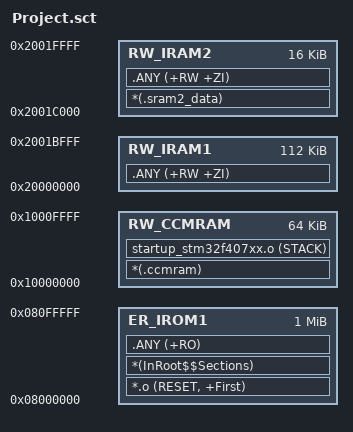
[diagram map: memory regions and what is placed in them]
; *************************************************************
; *** Scatter-Loading Description File generated by uVision ***
; *************************************************************

LR_IROM1 0x08000000 0x00100000  {    ; load region size_region
  ER_IROM1 0x08000000 0x00100000  {  ; load address = execution address
   *.o (RESET, +First)
   *(InRoot$$Sections)
   .ANY (+RO)
  }
  ; 1. CCMRAM：仅 CPU 访问的高速数据区
  ;CCM需要开时钟，可是时钟恰好就是开的！（默认复位置1）
  RW_CCMRAM 0x10000000 0x00010000 {
    *(.ccmram)                       ;被标志为.ccmram的段放这(手动)
    startup_stm32f407xx.o (STACK)    ;启动文件的stack也放这
  }
  ; 2. IRAM1：主内存 (112KB)
  RW_IRAM1 0x20000000 0x0001C000  {  ; RW data
   .ANY (+RW +ZI)
  }
  ; 3. IRAM2：DMA 优化区 (16KB)
  RW_IRAM2 0x2001C000 0x00004000  {
    *(.sram2_data)                    ; 被标志为.sram2_data的段放这(手动)
   .ANY (+RW +ZI)
  }
}

;使用：类型 变量 __attribute__((section("段")));
